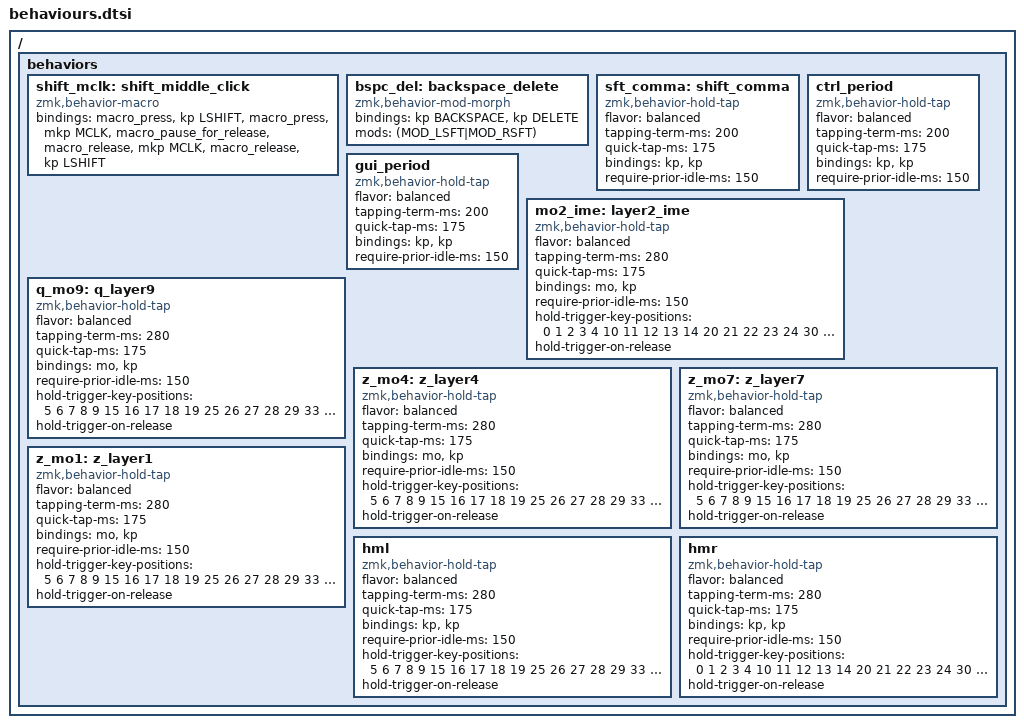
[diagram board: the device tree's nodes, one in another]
/ {
    behaviors {
        // Shift + 中央クリック マクロ
        shift_mclk: shift_middle_click {
            compatible = "zmk,behavior-macro";
            #binding-cells = <0>;
            bindings
                = <&macro_press &kp LSHIFT>
                , <&macro_press &mkp MCLK>
                , <&macro_pause_for_release>
                , <&macro_release &mkp MCLK>
                , <&macro_release &kp LSHIFT>
                ;
        };

        // Backspace/Delete切り替え
        bspc_del: backspace_delete {
            compatible = "zmk,behavior-mod-morph";
            #binding-cells = <0>;
            bindings = <&kp BACKSPACE>, <&kp DELETE>;
            mods = <(MOD_LSFT|MOD_RSFT)>;
        };

        // Shift/カンマ hold-tap（単押し→,、長押し→Shift）
        sft_comma: shift_comma {
            compatible = "zmk,behavior-hold-tap";
            #binding-cells = <2>;
            flavor = "balanced";
            tapping-term-ms = <200>;
            quick-tap-ms = <175>;
            bindings = <&kp>, <&kp>;
            require-prior-idle-ms = <150>;
        };

        // Ctrl/ピリオド hold-tap（単押し→.、長押し→Ctrl）
        ctrl_period: ctrl_period {
            compatible = "zmk,behavior-hold-tap";
            #binding-cells = <2>;
            flavor = "balanced";
            tapping-term-ms = <200>;
            quick-tap-ms = <175>;
            bindings = <&kp>, <&kp>;
            require-prior-idle-ms = <150>;
        };

        // GUI/ピリオド hold-tap（MAC用、単押し→.、長押し→GUI）
        gui_period: gui_period {
            compatible = "zmk,behavior-hold-tap";
            #binding-cells = <2>;
            flavor = "balanced";
            tapping-term-ms = <200>;
            quick-tap-ms = <175>;
            bindings = <&kp>, <&kp>;
            require-prior-idle-ms = <150>;
        };

        // mo2/半角全角 hold-tap（単押し→半角全角、長押し→レイヤー2）
        mo2_ime: layer2_ime {
            compatible = "zmk,behavior-hold-tap";
            #binding-cells = <2>;
            flavor = "balanced";
            tapping-term-ms = <280>;
            quick-tap-ms = <175>;
            bindings = <&mo>, <&kp>;
            require-prior-idle-ms = <150>;
            hold-trigger-key-positions = <0 1 2 3 4 10 11 12 13 14 20 21 22 23 24 30 31 32 34 33>;
            hold-trigger-on-release;
        };

        // Q/mo9 hold-tap（Q長押し→レイヤー9）
        q_mo9: q_layer9 {
            compatible = "zmk,behavior-hold-tap";
            #binding-cells = <2>;
            flavor = "balanced";
            tapping-term-ms = <280>;
            quick-tap-ms = <175>;
            bindings = <&mo>, <&kp>;
            require-prior-idle-ms = <150>;
            hold-trigger-key-positions = <5 6 7 8 9 15 16 17 18 19 25 26 27 28 29 33 34 31 32>;
            hold-trigger-on-release;
        };

        // Z/mo4 hold-tap（レイヤー3でZ長押し→レイヤー4）
        z_mo4: z_layer4 {
            compatible = "zmk,behavior-hold-tap";
            #binding-cells = <2>;
            flavor = "balanced";
            tapping-term-ms = <280>;
            quick-tap-ms = <175>;
            bindings = <&mo>, <&kp>;
            require-prior-idle-ms = <150>;
            hold-trigger-key-positions = <5 6 7 8 9 15 16 17 18 19 25 26 27 28 29 33 34 31 32>;
            hold-trigger-on-release;
        };

        // Z/mo7 hold-tap（レイヤー6でZ長押し→レイヤー7）
        z_mo7: z_layer7 {
            compatible = "zmk,behavior-hold-tap";
            #binding-cells = <2>;
            flavor = "balanced";
            tapping-term-ms = <280>;
            quick-tap-ms = <175>;
            bindings = <&mo>, <&kp>;
            require-prior-idle-ms = <150>;
            hold-trigger-key-positions = <5 6 7 8 9 15 16 17 18 19 25 26 27 28 29 33 34 31 32>;
            hold-trigger-on-release;
        };


        // Z/mo1 hold-tap（hmlベース）
        z_mo1: z_layer1 {
            compatible = "zmk,behavior-hold-tap";
            #binding-cells = <2>;
            flavor = "balanced";
            tapping-term-ms = <280>;
            quick-tap-ms = <175>;
            bindings = <&mo>, <&kp>;
            require-prior-idle-ms = <150>;
            hold-trigger-key-positions = <5 6 7 8 9 15 16 17 18 19 25 26 27 28 29 33 34 31 32>;
            hold-trigger-on-release;
        };

        // 基本的なホームロー修飾キー
        hml: hml {
            compatible = "zmk,behavior-hold-tap";
            #binding-cells = <2>;
            flavor = "balanced";
            tapping-term-ms = <280>;
            quick-tap-ms = <175>;
            bindings = <&kp>, <&kp>;
            require-prior-idle-ms = <150>;
            hold-trigger-key-positions = <5 6 7 8 9 15 16 17 18 19 25 26 27 28 29 33 34 31 32>;
            hold-trigger-on-release;
        };

        hmr: hmr {
            compatible = "zmk,behavior-hold-tap";
            #binding-cells = <2>;
            flavor = "balanced";
            tapping-term-ms = <280>;
            quick-tap-ms = <175>;
            bindings = <&kp>, <&kp>;
            require-prior-idle-ms = <150>;
            hold-trigger-key-positions = <0 1 2 3 4 10 11 12 13 14 20 21 22 23 24 30 31 32 34 33>;
            hold-trigger-on-release;
        };
    };
};
